VERSION ""

NS_ :

BS_:

BU_:

BO_ 3221225472 VECTOR__INDEPENDENT_SIG_MSG: 0 Vector__XXX
 SG_ VSM_GS_source_Req : 0|3@1+ (1,0) [1|4] "" Vector__XXX
 SG_ VSM_GS_Req : 0|4@1+ (1,0) [0|15] "" Vector__XXX
 SG_ VSM_Allowed_States_6 : 0|1@1+ (1,0) [0|1] "" Vector__XXX
 SG_ VSM_Allowed_States_5 : 0|1@1+ (1,0) [0|1] "" Vector__XXX
 SG_ VSM_Allowed_States_4 : 0|1@1+ (1,0) [0|1] "" Vector__XXX
 SG_ VSM_Allowed_States_3 : 0|1@1+ (1,0) [0|1] "" Vector__XXX
 SG_ VSM_Allowed_States_2 : 0|1@1+ (1,0) [0|1] "" Vector__XXX
 SG_ VSM_Allowed_States_1 : 0|1@1+ (1,0) [0|1] "" Vector__XXX
 SG_ ABB_AnInSig4 : 0|16@1+ (0.0005,0) [0|32.7675] "V" Vector__XXX
 SG_ ABB_AnInSig3 : 0|16@1+ (0.0005,0) [0|32.7675] "V" Vector__XXX
 SG_ ABB_AnInSig2 : 0|16@1+ (0.0005,0) [0|32.7675] "V" Vector__XXX
 SG_ ABB_AnInSig1 : 0|16@1+ (0.0005,0) [0|32.7675] "V" Vector__XXX
 SG_ VSM_valid : 0|1@1+ (1,0) [0|1] "" Vector__XXX
 SG_ HMI3_GS_Req_valid : 0|1@1+ (1,0) [0|1] "" Vector__XXX
 SG_ HMI3_GS_Req : 0|4@1+ (1,0) [0|15] "" Vector__XXX
 SG_ gb_interlock_state : 0|3@1+ (1,0) [0|7] "" Vector__XXX
 SG_ AI_GS_Req_valid : 0|1@1+ (1,0) [0|1] "" Vector__XXX
 SG_ AI_GS_Req : 0|4@1+ (1,0) [0|15] "" Vector__XXX

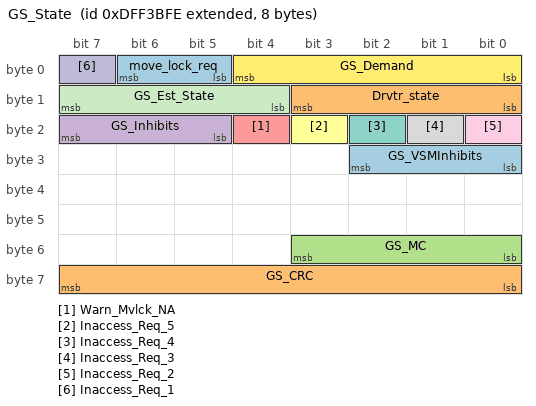
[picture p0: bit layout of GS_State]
BO_ 2382314494 GS_State: 8 Vector__XXX
 SG_ GS_VSMInhibits : 24|3@1+ (1,0) [0|7] "" Vector__XXX
 SG_ GS_CRC : 56|8@1+ (1,0) [0|255] "" Vector__XXX
 SG_ GS_MC : 48|4@1+ (1,0) [0|15] "" Vector__XXX
 SG_ GS_Inhibits : 21|3@1+ (1,0) [0|7] "" Vector__XXX
 SG_ Warn_Mvlck_NA : 20|1@1+ (1,0) [0|1] "" Vector__XXX
 SG_ Inaccess_Req_5 : 19|1@1+ (1,0) [0|1] "" Vector__XXX
 SG_ Inaccess_Req_4 : 18|1@1+ (1,0) [0|1] "" Vector__XXX
 SG_ Inaccess_Req_3 : 17|1@1+ (1,0) [0|1] "" Vector__XXX
 SG_ Inaccess_Req_2 : 16|1@1+ (1,0) [0|1] "" Vector__XXX
 SG_ Inaccess_Req_1 : 7|1@1+ (1,0) [0|1] "" Vector__XXX
 SG_ GS_Est_State : 12|4@1+ (1,0) [0|15] "" Vector__XXX
 SG_ GS_Demand : 0|5@1+ (1,0) [0|31] "" Vector__XXX
 SG_ move_lock_req : 5|2@1+ (1,0) [0|3] "" Vector__XXX
 SG_ Drvtr_state : 8|4@1+ (1,0) [0|15] "" Vector__XXX

CM_ BO_ 3221225472 "This is a message for not used signals, created by Vector CANdb++ DBC OLE DB Provider.";
CM_ SG_ 3221225472 VSM_GS_source_Req "Signal for choosing of Gear Selector request source";
CM_ SG_ 3221225472 VSM_GS_Req "Gear Selector Request from VSM";
CM_ SG_ 3221225472 VSM_Allowed_States_6 "The allowance of ParkReverse Gear Selector state";
CM_ SG_ 3221225472 VSM_Allowed_States_5 "The allowance of ParkDrive Gear Selector state";
CM_ SG_ 3221225472 VSM_Allowed_States_4 "The allowance of Reverse Gear Selector state";
CM_ SG_ 3221225472 VSM_Allowed_States_3 "The allowance of Drive Gear Selector state";
CM_ SG_ 3221225472 VSM_Allowed_States_2 "The allowance of Neutral Gear Selector state";
CM_ SG_ 3221225472 VSM_Allowed_States_1 "The allowance of Park Gear Selector state";
CM_ SG_ 3221225472 ABB_AnInSig4 "Analog button block driver: Analog input signal 4 [V]";
CM_ SG_ 3221225472 ABB_AnInSig3 "Analog button block driver: Analog input signal 3 [V]";
CM_ SG_ 3221225472 ABB_AnInSig2 "Analog button block driver: Analog input signal 2 [V]";
CM_ SG_ 3221225472 ABB_AnInSig1 "Analog button block driver: Analog input signal 1 [V]";
CM_ SG_ 3221225472 HMI3_GS_Req_valid "Validity of the HMI 3 Gear Selector request";
CM_ SG_ 3221225472 HMI3_GS_Req "Gear Selector Request from HMI 3";
CM_ SG_ 3221225472 gb_interlock_state "State of the move-locking device calculated by Gear Selector module";
CM_ SG_ 3221225472 AI_GS_Req_valid "Validity of the Gear selector request from A I";
CM_ SG_ 3221225472 AI_GS_Req "Gear selector request from AI";
CM_ BO_ 2382314494 "Contains information about states of Gear Selector, Drivetrain, Gearbox Interlock and GS Request Sources.
";
CM_ SG_ 2382314494 GS_VSMInhibits "Gear Selector Request from VSM";
CM_ SG_ 2382314494 GS_Inhibits "Gear Selector Request from VSM";
CM_ SG_ 2382314494 Inaccess_Req_5 "Flag  of the VSM request inaccessibility. If it is true then VSM GS request signal is valid but not correct in current circumstances";
CM_ SG_ 2382314494 Inaccess_Req_4 "Flag  of the HMI3 request inaccessibility. If it is true then HMI3 GS request signal is valid but not correct in current circumstances";
CM_ SG_ 2382314494 Inaccess_Req_3 "Flag  of the HMI2 request inaccessibility. If it is true then HMI2 GS request signal is valid but not correct in current circumstances";
CM_ SG_ 2382314494 Inaccess_Req_2 "Flag  of the HMI1 request inaccessibility. If it is true then HMI1 GS request signal is valid but not correct in current circumstances";
CM_ SG_ 2382314494 Inaccess_Req_1 "Flag  of the AI request inaccessibility. If it is true then AI GS request signal is valid but not correct in current circumstances";
CM_ SG_ 2382314494 GS_Est_State "Gear Selector State estimated by Gear Selector module";
CM_ SG_ 2382314494 GS_Demand "Gear selecor demand";
CM_ SG_ 2382314494 move_lock_req "Move-locking device request";
CM_ SG_ 2382314494 Drvtr_state "Drivetrain state calculated by Gear Selector module";
BA_DEF_ BO_  "Producer" STRING ;
BA_DEF_ SG_  "SigType" ENUM  "Default","Range","RangeSigned","ASCII","Discrete","Control","ReferencePGN","DTC","StringDelimiter","StringLength","StringLengthControl","MessageCounter","MessageChecksum";
BA_DEF_ SG_  "GenSigEVName" STRING ;
BA_DEF_ SG_  "GenSigILSupport" ENUM  "No","Yes";
BA_DEF_ SG_  "GenSigSendType" ENUM  "Cyclic","OnWrite","OnWriteWithRepetition","OnChange","OnChangeWithRepetition","IfActive","IfActiveWithRepetition","NoSigSendType";
BA_DEF_ SG_  "GenSigStartValue" INT 0 2147483647;
BA_DEF_ BO_  "GenMsgILSupport" ENUM  "No","Yes";
BA_DEF_ BU_  "NmStationAddress" INT 0 255;
BA_DEF_ BO_  "GenMsgSendType" ENUM  "cyclic","NotUsed","IfActive","NotUsed","NotUsed","NotUsed","NotUsed","NotUsed","noMsgSendType";
BA_DEF_ BO_  "GenMsgRequestable" INT 0 1;
BA_DEF_ BO_  "GenMsgCycleTime" INT 0 3600000;
BA_DEF_  "DBName" STRING ;
BA_DEF_  "BusType" STRING ;
BA_DEF_  "ProtocolType" STRING ;
BA_DEF_ BO_  "VFrameFormat" ENUM  "StandardCAN","ExtendedCAN","reserved","J1939PG";
BA_DEF_DEF_ "Producer" "DTS" ;
BA_DEF_DEF_  "SigType" "Default";
BA_DEF_DEF_  "GenSigEVName" "Env@Nodename_@Signame";
BA_DEF_DEF_  "GenSigILSupport" "Yes";
BA_DEF_DEF_  "GenSigSendType" "NoSigSendType";
BA_DEF_DEF_  "GenSigStartValue" 0;
BA_DEF_DEF_  "GenMsgILSupport" "Yes";
BA_DEF_DEF_  "NmStationAddress" 254;
BA_DEF_DEF_  "GenMsgSendType" "noMsgSendType";
BA_DEF_DEF_  "GenMsgRequestable" 1;
BA_DEF_DEF_  "GenMsgCycleTime" 0;
BA_DEF_DEF_  "DBName" "";
BA_DEF_DEF_  "BusType" "CAN";
BA_DEF_DEF_  "ProtocolType" "J1939";
BA_DEF_DEF_  "VFrameFormat" "J1939PG";
BA_ "DBName" "GearSelector";
BA_ "GenMsgCycleTime" BO_ 2382314494 40;
BA_ "GenMsgSendType" BO_ 2382314494 0;
BA_ "GenSigStartValue" SG_ 3221225472 VSM_GS_source_Req 2;
BA_ "GenSigStartValue" SG_ 3221225472 VSM_GS_Req 3;
BA_ "GenSigStartValue" SG_ 3221225472 HMI3_GS_Req 3;
BA_ "GenSigStartValue" SG_ 3221225472 AI_GS_Req 3;
BA_ "SigType" SG_ 2382314494 GS_CRC 12;
BA_ "SigType" SG_ 2382314494 GS_MC 11;
BA_ "GenSigStartValue" SG_ 2382314494 GS_Demand 3;
VAL_ 3221225472 VSM_GS_Req 14 "Park_Reverse" 13 "Park_Drive" 5 "Reverse" 4 "Drive" 3 "Neutral" 2 "Park" ;
VAL_ 3221225472 HMI3_GS_Req 14 "Park_Reverse" 13 "Park_Drive" 5 "Reverse" 4 "Drive" 3 "Neutral" 2 "Park" ;
VAL_ 3221225472 gb_interlock_state 4 "Changing" 3 "Error" 2 "N_A" 1 "Unlocked" 0 "Locked" ;
VAL_ 3221225472 AI_GS_Req 14 "Park_Reverse" 13 "Park_Drive" 5 "Reverse" 4 "Drive" 3 "Neutral" 2 "Park" ;
VAL_ 2382314494 GS_VSMInhibits 7 "NA" 6 "NVSMInhib" 1 "RDDoorInhib" 0 "NoVSMNotif" 5 "NChargeInhib" 4 "RDVSMInhib" 3 "RDChargInhib" 2 "RDRampInhib" ;
VAL_ 2382314494 GS_Inhibits 7 "NA" 6 "Error" 1 "RDSpeedInhib" 0 "NoNotification" 5 "RNDChargeInhib" 4 "PSpeedInhib" 3 "NBrakeInhib" 2 "RDBrakeInhib" ;
VAL_ 2382314494 GS_Est_State 14 "Park_Reverse" 13 "Park_Drive" 11 "Change_in_Progress" 10 "Reverse_PErr" 9 "Drive_PErr" 8 "Neutral_PErr" 7 "Park_DT_Err" 6 "DT_Err" 5 "Reverse" 4 "Drive" 3 "Neutral" 2 "Park" 1 "Error" 0 "N_A" ;
VAL_ 2382314494 GS_Demand 16 "Reverse_ NoAction" 15 "Drive_NoAction" 14 "Park_Reverse" 13 "Park_Drive" 12 "Neutral_NoAction" 5 "Reverse" 4 "Drive" 3 "Neutral" 2 "Park" ;
VAL_ 2382314494 move_lock_req 2 "Take_no_action" 1 "Unlocked" 0 "Locked" ;
VAL_ 2382314494 Drvtr_state 11 "Change_in_Progress" 1 "Error" 0 "N_A" 5 "Reverse" 4 "Drive" 3 "Neutral" ;
